VERSION ""

NS_ :

BS_:

BU_: Sensors VCU

BO_ 1628 XCP_msg: 8 Sensors

BO_ 0 LOJNK: 8 Vector__XXX

BO_ 2047 HIJNK: 8 Vector__XXX

BO_ 515 CMD03: 8 VCU
 SG_ DataChan2_s3 : 31|16@0+ (1,0) [0|0] ""  Sensors
 SG_ PageSel_s3 : 3|4@0+ (1,0) [0|0] ""  Sensors
 SG_ SensYLoc_s3 m2 : 15|16@0- (0.001,0) [0|0] "m"  Sensors
 SG_ SensXLoc_s3 m1 : 15|16@0- (0.001,0) [0|0] "m"  Sensors
 SG_ SensRotation_s3 m0 : 15|12@0- (0.1,0) [0|0] "deg"  Sensors
 SG_ SensOrientation_s3 m0 : 19|1@0+ (1,0) [0|0] ""  Sensors
 SG_ CRC8_s3 : 47|8@0+ (1,0) [0|0] ""  Sensors
 SG_ Cntr_s3 M : 7|4@0+ (1,0) [0|0] ""  Sensors
 SG_ BumperLoc_s3 m0 : 18|1@0+ (1,0) [0|0] ""  Sensors

BO_ 514 CMD02: 8 VCU
 SG_ SensYLoc_s2 m2 : 15|16@0- (0.001,0) [0|0] "m"  Sensors
 SG_ SensXLoc_s2 m1 : 15|16@0- (0.001,0) [0|0] "m"  Sensors
 SG_ SensRotation_s2 m0 : 15|12@0- (0.1,0) [0|0] "deg"  Sensors
 SG_ SensOrientation_s2 m0 : 19|1@0+ (1,0) [0|0] ""  Sensors
 SG_ PageSel_s2 : 3|4@0+ (1,0) [0|0] ""  Sensors
 SG_ DataChan2_s2 : 31|16@0+ (1,0) [0|0] ""  Sensors
 SG_ CRC8_s2 : 47|8@0+ (1,0) [0|0] ""  Sensors
 SG_ Cntr_s2 M : 7|4@0+ (1,0) [0|0] ""  Sensors
 SG_ BumperLoc_s2 m0 : 18|1@0+ (1,0) [0|0] ""  Sensors

BO_ 777 TRG9: 8 Sensors
 SG_ VeloYFilt m2 : 49|10@0- (0.1,-20) [-71.2|31.1] "m/s"  VCU
 SG_ ObjectType m2 : 51|2@0+ (1,0) [0|3] ""  VCU
 SG_ VeloXFilt m2 : 11|10@0- (0.1,-20) [-71.2|31.1] "m/s"  VCU
 SG_ RangeFilt m2 : 7|12@0+ (0.05,0) [0|204.75] "m"  VCU
 SG_ BearFilt m2 : 17|10@0- (0.2,0) [0|0] "deg"  VCU
 SG_ sID M : 43|4@0+ (1,0) [0|4] ""  VCU
 SG_ tID m2 : 35|4@0+ (1,0) [0|0] ""  VCU
 SG_ TargetType m2 : 55|4@0+ (1,0) [0|0] ""  VCU
 SG_ Quality m2 : 39|4@0+ (1,0) [0|0] ""  VCU
 SG_ mCntr m2 : 47|4@0+ (1,0) [0|0] ""  VCU

BO_ 776 TRG8: 8 Sensors
 SG_ VeloYFilt m2 : 49|10@0- (0.1,-20) [-71.2|31.1] "m/s"  VCU
 SG_ ObjectType m2 : 51|2@0+ (1,0) [0|3] ""  VCU
 SG_ VeloXFilt m2 : 11|10@0- (0.1,-20) [-71.2|31.1] "m/s"  VCU
 SG_ RangeFilt m2 : 7|12@0+ (0.05,0) [0|204.75] "m"  VCU
 SG_ BearFilt m2 : 17|10@0- (0.2,0) [0|0] "deg"  VCU
 SG_ sID M : 43|4@0+ (1,0) [1|4] ""  VCU
 SG_ tID m2 : 35|4@0+ (1,0) [0|0] ""  VCU
 SG_ TargetType m2 : 55|4@0+ (1,0) [0|0] ""  VCU
 SG_ Quality m2 : 39|4@0+ (1,0) [0|0] ""  VCU
 SG_ mCntr m2 : 47|4@0+ (1,0) [0|0] ""  VCU

BO_ 775 TRG7: 8 Sensors
 SG_ VeloYFilt m2 : 49|10@0- (0.1,-20) [-71.2|31.1] "m/s"  VCU
 SG_ ObjectType m2 : 51|2@0+ (1,0) [0|3] ""  VCU
 SG_ VeloXFilt m2 : 11|10@0- (0.1,-20) [-71.2|31.1] "m/s"  VCU
 SG_ RangeFilt m2 : 7|12@0+ (0.05,0) [0|204.75] "m"  VCU
 SG_ BearFilt m2 : 17|10@0- (0.2,0) [0|0] "deg"  VCU
 SG_ sID M : 43|4@0+ (1,0) [1|4] ""  VCU
 SG_ tID m2 : 35|4@0+ (1,0) [0|0] ""  VCU
 SG_ TargetType m2 : 55|4@0+ (1,0) [0|0] ""  VCU
 SG_ Quality m2 : 39|4@0+ (1,0) [0|0] ""  VCU
 SG_ mCntr m2 : 47|4@0+ (1,0) [0|0] ""  VCU

BO_ 774 TRG6: 8 Sensors
 SG_ VeloYFilt m2 : 49|10@0- (0.1,-20) [-71.2|31.1] "m/s"  VCU
 SG_ ObjectType m2 : 51|2@0+ (1,0) [0|3] ""  VCU
 SG_ VeloXFilt m2 : 11|10@0- (0.1,-20) [-71.2|31.1] "m/s"  VCU
 SG_ RangeFilt m2 : 7|12@0+ (0.05,0) [0|204.75] "m"  VCU
 SG_ BearFilt m2 : 17|10@0- (0.2,0) [0|0] "deg"  VCU
 SG_ sID M : 43|4@0+ (1,0) [1|4] ""  VCU
 SG_ tID m2 : 35|4@0+ (1,0) [0|0] ""  VCU
 SG_ TargetType m2 : 55|4@0+ (1,0) [0|0] ""  VCU
 SG_ Quality m2 : 39|4@0+ (1,0) [0|0] ""  VCU
 SG_ mCntr m2 : 47|4@0+ (1,0) [0|0] ""  VCU

BO_ 773 TRG5: 8 Sensors
 SG_ VeloYFilt m2 : 49|10@0- (0.1,-20) [-71.2|31.1] "m/s"  VCU
 SG_ ObjectType m2 : 51|2@0+ (1,0) [0|3] ""  VCU
 SG_ VeloXFilt m2 : 11|10@0- (0.1,-20) [-71.2|31.1] "m/s"  VCU
 SG_ RangeFilt m2 : 7|12@0+ (0.05,0) [0|204.75] "m"  VCU
 SG_ BearFilt m2 : 17|10@0- (0.2,0) [0|0] "deg"  VCU
 SG_ sID M : 43|4@0+ (1,0) [1|4] ""  VCU
 SG_ tID m2 : 35|4@0+ (1,0) [0|0] ""  VCU
 SG_ TargetType m2 : 55|4@0+ (1,0) [0|0] ""  VCU
 SG_ Quality m2 : 39|4@0+ (1,0) [0|0] ""  VCU
 SG_ mCntr m2 : 47|4@0+ (1,0) [0|0] ""  VCU

BO_ 772 TRG4: 8 Sensors
 SG_ VeloYFilt m2 : 49|10@0- (0.1,-20) [-71.2|31.1] "m/s"  VCU
 SG_ ObjectType m2 : 51|2@0+ (1,0) [0|3] ""  VCU
 SG_ VeloXFilt m2 : 11|10@0- (0.1,-20) [-71.2|31.1] "m/s"  VCU
 SG_ RangeFilt m2 : 7|12@0+ (0.05,0) [0|204.75] "m"  VCU
 SG_ BearFilt m2 : 17|10@0- (0.2,0) [0|0] "deg"  VCU
 SG_ sID M : 43|4@0+ (1,0) [1|4] ""  VCU
 SG_ tID m2 : 35|4@0+ (1,0) [0|0] ""  VCU
 SG_ TargetType m2 : 55|4@0+ (1,0) [0|0] ""  VCU
 SG_ Quality m2 : 39|4@0+ (1,0) [0|0] ""  VCU
 SG_ mCntr m2 : 47|4@0+ (1,0) [0|0] ""  VCU

BO_ 771 TRG3: 8 Sensors
 SG_ VeloYFilt m2 : 49|10@0- (0.1,-20) [-71.2|31.1] "m/s"  VCU
 SG_ ObjectType m2 : 51|2@0+ (1,0) [0|3] ""  VCU
 SG_ VeloXFilt m2 : 11|10@0- (0.1,-20) [-71.2|31.1] "m/s"  VCU
 SG_ RangeFilt m2 : 7|12@0+ (0.05,0) [0|204.75] "m"  VCU
 SG_ BearFilt m2 : 17|10@0- (0.2,0) [0|0] "deg"  VCU
 SG_ sID M : 43|4@0+ (1,0) [1|4] ""  VCU
 SG_ tID m2 : 35|4@0+ (1,0) [0|0] ""  VCU
 SG_ TargetType m2 : 55|4@0+ (1,0) [0|0] ""  VCU
 SG_ Quality m2 : 39|4@0+ (1,0) [0|0] ""  VCU
 SG_ mCntr m2 : 47|4@0+ (1,0) [0|0] ""  VCU

BO_ 770 TRG2: 8 Sensors
 SG_ VeloYFilt m2 : 49|10@0- (0.1,-20) [-71.2|31.1] "m/s"  VCU
 SG_ ObjectType m2 : 51|2@0+ (1,0) [0|3] ""  VCU
 SG_ VeloXFilt m2 : 11|10@0- (0.1,-20) [-71.2|31.1] "m/s"  VCU
 SG_ RangeFilt m2 : 7|12@0+ (0.05,0) [0|204.75] "m"  VCU
 SG_ BearFilt m2 : 17|10@0- (0.2,0) [-102.4|102.2] "deg"  VCU
 SG_ sID M : 43|4@0+ (1,0) [1|4] ""  VCU
 SG_ tID m2 : 35|4@0+ (1,0) [0|0] ""  VCU
 SG_ TargetType m2 : 55|4@0+ (1,0) [0|0] ""  VCU
 SG_ Quality m2 : 39|4@0+ (1,0) [0|0] ""  VCU
 SG_ mCntr m2 : 47|4@0+ (1,0) [0|0] ""  VCU

BO_ 769 TRG1: 8 Sensors
 SG_ VeloYFilt m2 : 49|10@0- (0.1,-20) [-71.2|31.1] "m/s"  VCU
 SG_ ObjectType m2 : 51|2@0+ (1,0) [0|3] ""  VCU
 SG_ VeloXFilt m2 : 11|10@0- (0.1,-20) [-71.2|31.1] "m/s"  VCU
 SG_ RangeFilt m2 : 7|12@0+ (0.05,0) [0|204.75] "m"  VCU
 SG_ BearFilt m2 : 17|10@0- (0.2,0) [-102.4|102.2] "deg"  VCU
 SG_ sID M : 43|4@0+ (1,0) [1|4] ""  VCU
 SG_ tID m2 : 35|4@0+ (1,0) [0|0] ""  VCU
 SG_ TargetType m2 : 55|4@0+ (1,0) [0|0] ""  VCU
 SG_ Quality m2 : 39|4@0+ (1,0) [0|0] ""  VCU
 SG_ mCntr m2 : 47|4@0+ (1,0) [0|0] ""  VCU

BO_ 768 TRG0: 8 Sensors
 SG_ VeloYFilt m2 : 49|10@0- (0.1,-20) [-71.2|31.1] "m/s"  VCU
 SG_ ObjectType m2 : 51|2@0+ (1,0) [0|3] ""  VCU
 SG_ VeloXFilt m2 : 11|10@0- (0.1,-20) [-71.2|31.1] "m/s"  VCU
 SG_ RangeFilt m2 : 7|12@0+ (0.05,0) [0|204.75] "m"  VCU
 SG_ BearFilt m2 : 17|10@0- (0.2,0) [-102.4|102.2] "deg"  VCU
 SG_ sID M : 43|4@0+ (1,0) [1|4] ""  VCU
 SG_ tID m2 : 35|4@0+ (1,0) [0|0] ""  VCU
 SG_ TargetType m2 : 55|4@0+ (1,0) [0|0] ""  VCU
 SG_ Quality m2 : 39|4@0+ (1,0) [0|0] ""  VCU
 SG_ mCntr m2 : 47|4@0+ (1,0) [0|0] ""  VCU

BO_ 1024 STAT: 8 Sensors
 SG_ AppSubVer_stat m9 : 15|8@0+ (1,0) [0|0] ""  Sensors
 SG_ AppPlatType_stat m9 : 7|8@0+ (1,0) [0|0] ""  Sensors
 SG_ AppCust_stat m10 : 15|8@0+ (1,0) [0|0] ""  Sensors
 SG_ CRC_Stat : 55|16@0+ (1,0) [0|0] ""  Sensors
 SG_ BumperLoc_stat m4 : 10|1@0+ (1,0) [0|0] ""  Sensors
 SG_ VCO_DAC m8 : 7|16@0- (0.1,0) [0|0] "deg"  Sensors
 SG_ SensYLoc_stat m6 : 7|16@0- (0.001,0) [0|0] "m"  Sensors
 SG_ SensXLoc_stat m5 : 7|16@0- (0.001,0) [0|0] "m"  Sensors
 SG_ SensRotation_stat m7 : 7|12@0- (0.1,0) [0|0] "deg"  Sensors
 SG_ SensOrientation_stat m4 : 11|1@0+ (1,0) [0|0] ""  Sensors
 SG_ PlatformType_stat m4 : 15|4@0+ (1,0) [0|15] ""  Sensors
 SG_ HW_Version m1 : 7|16@0- (1,0) [0|0] ""  Sensors
 SG_ BootSWVer_Minor m3 : 15|8@0- (1,0) [0|0] ""  Sensors
 SG_ BootSWVer_Major m3 : 7|8@0- (1,0) [0|0] ""  Sensors
 SG_ AppSWVer_Minor m2 : 15|8@0- (1,0) [0|0] ""  Sensors
 SG_ AppSWVer_Major m2 : 7|8@0- (1,0) [0|0] ""  Sensors
 SG_ PCU_Temp m0 : 15|8@0- (1,0) [0|0] "deg"  Sensors
 SG_ VCO_Temp m0 : 7|8@0- (1,0) [0|0] "deg"  Sensors
 SG_ SenMode_Stat : 39|4@0+ (1,0) [0|0] ""  Sensors
 SG_ Sen_Blockage : 35|2@0+ (1,0) [0|0] ""  Sensors
 SG_ MsgCntr_Stat M : 47|4@0+ (1,0) [0|0] ""  Sensors
 SG_ mSenNumb_Stat : 43|4@0+ (1,0) [0|0] ""  Sensors
 SG_ DiagCode_Stat : 23|16@0+ (1,0) [0|0] ""  Sensors

BO_ 256 SYNC: 8 VCU
 SG_ ProtocolRev_sync m0 : 39|8@0+ (1,0) [0|0] ""  Sensors
 SG_ PlatformType_sync m0 : 23|8@0+ (1,0) [0|255] ""  Sensors
 SG_ Msg_Cntr_sync M : 31|4@0+ (1,0) [0|0] ""  Sensors
 SG_ Vehicle_Yaw : 47|12@0- (0.05,0) [0|0] "deg/s"  Sensors
 SG_ Vehicle_Velo : 51|12@0- (0.035,0) [0|0] "m/s"  Sensors
 SG_ mode_s4 : 11|4@0+ (1,0) [0|0] ""  Sensors
 SG_ mode_s3 : 15|4@0+ (1,0) [0|0] ""  Sensors
 SG_ mode_s2 : 3|4@0+ (1,0) [0|0] ""  Sensors
 SG_ mode_s1 : 7|4@0+ (1,0) [0|0] ""  Sensors

BO_ 897 MEAS2: 8 Sensors
 SG_ SenNum_MD2 M : 43|4@0+ (1,0) [1|4] ""  VCU
 SG_ MD9 m1 : 15|8@0- (0.5,0) [0|0] "dB"  VCU
 SG_ MD8 m1 : 7|8@0- (1,0) [0|0] ""  VCU
 SG_ MD2_Msg_Cntr m1 : 47|4@0+ (1,0) [0|0] ""  VCU
 SG_ MD14 m1 : 55|8@0- (1,0) [0|0] "%"  VCU
 SG_ MD13 m1 : 63|8@0- (1,0) [0|0] ""  VCU
 SG_ MD12 m1 : 39|8@0- (1,0) [0|0] ""  VCU
 SG_ MD11 m1 : 31|8@0- (0.1,0) [0|0] "V"  VCU
 SG_ MD10 m1 : 23|8@0- (0.5,0) [0|0] "dB"  VCU

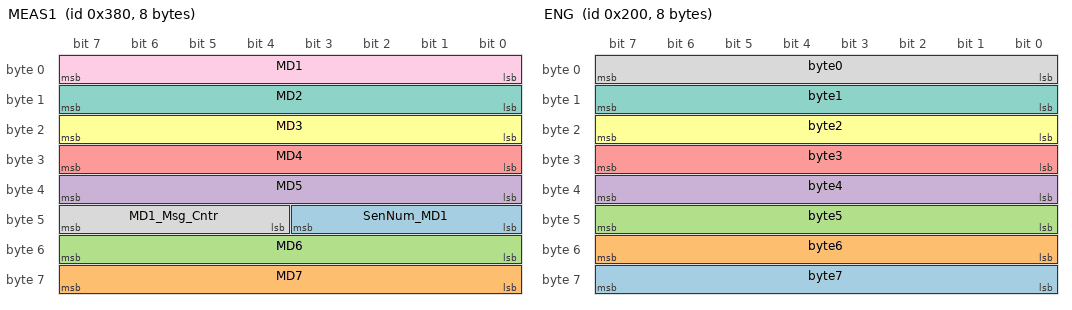
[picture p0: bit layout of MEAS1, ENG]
BO_ 896 MEAS1: 8 Sensors
 SG_ SenNum_MD1 : 43|4@0+ (1,0) [0|15] ""  VCU
 SG_ MD7 : 63|8@0- (1,0) [0|0] ""  VCU
 SG_ MD6 : 55|8@0- (1,0) [0|0] ""  VCU
 SG_ MD5 : 39|8@0- (0.5,0) [0|0] "m/s"  VCU
 SG_ MD4 : 31|8@0- (0.5,0) [0|0] "dB"  VCU
 SG_ MD3 : 23|8@0- (0.5,0) [0|0] "dB"  VCU
 SG_ MD2 : 15|8@0- (0.5,0) [0|0] "dB"  VCU
 SG_ MD1_Msg_Cntr : 47|4@0+ (1,0) [0|0] ""  VCU
 SG_ MD1 : 7|8@0- (0.6,0) [0|0] "dB"  VCU

BO_ 1023 ERR: 8 Sensors
 SG_ ErrorState_9 : 19|2@0+ (1,0) [0|0] ""  VCU
 SG_ ErrorState_8 : 17|2@0+ (1,0) [0|0] ""  VCU
 SG_ ErrorState_7 : 15|2@0+ (1,0) [0|0] ""  VCU
 SG_ ErrorState_6 : 13|2@0+ (1,0) [0|0] ""  VCU
 SG_ ErrorState_5 : 11|2@0+ (1,0) [0|0] ""  VCU
 SG_ ErrorState_4 : 9|2@0+ (1,0) [0|0] ""  VCU
 SG_ ErrorState_3 : 7|2@0+ (1,0) [0|0] ""  VCU
 SG_ ErrorState_27 : 63|2@0+ (1,0) [0|0] ""  VCU
 SG_ ErrorState_26 : 61|2@0+ (1,0) [0|0] ""  VCU
 SG_ ErrorState_25 : 59|2@0+ (1,0) [0|0] ""  VCU
 SG_ ErrorState_24 : 57|2@0+ (1,0) [0|0] ""  VCU
 SG_ ErrorState_23 : 55|2@0+ (1,0) [0|0] ""  VCU
 SG_ ErrorState_22 : 53|2@0+ (1,0) [0|0] ""  VCU
 SG_ ErrorState_21 : 51|2@0+ (1,0) [0|0] ""  VCU
 SG_ ErrorState_20 : 49|2@0+ (1,0) [0|0] ""  VCU
 SG_ ErrorState_2 : 5|2@0+ (1,0) [0|0] ""  VCU
 SG_ ErrorState_19 : 39|2@0+ (1,0) [0|0] ""  VCU
 SG_ ErrorState_18 : 37|2@0+ (1,0) [0|0] ""  VCU
 SG_ ErrorState_17 : 35|2@0+ (1,0) [0|0] ""  VCU
 SG_ ErrorState_16 : 33|2@0+ (1,0) [0|0] ""  VCU
 SG_ ErrorState_15 : 31|2@0+ (1,0) [0|0] ""  VCU
 SG_ ErrorState_14 : 29|2@0+ (1,0) [0|0] ""  VCU
 SG_ ErrorState_13 : 27|2@0+ (1,0) [0|0] ""  VCU
 SG_ ErrorState_12 : 25|2@0+ (1,0) [0|0] ""  VCU
 SG_ ErrorState_11 : 23|2@0+ (1,0) [0|0] ""  VCU
 SG_ ErrorState_10 : 21|2@0+ (1,0) [0|0] ""  VCU
 SG_ ErrorState_1 : 3|2@0+ (1,0) [0|0] ""  VCU
 SG_ ErrorState_0 : 1|2@0+ (1,0) [0|0] ""  VCU
 SG_ Err_SenNum : 43|4@0+ (1,0) [0|0] ""  VCU
 SG_ Err_MsgCntr : 47|4@0+ (1,0) [0|0] ""  VCU

BO_ 512 ENG: 8 VCU
 SG_ byte7 : 63|8@0+ (1,0) [0|255] ""  Sensors
 SG_ byte6 : 55|8@0+ (1,0) [0|255] ""  Sensors
 SG_ byte5 : 47|8@0+ (1,0) [0|255] ""  Sensors
 SG_ byte4 : 39|8@0+ (1,0) [0|255] ""  Sensors
 SG_ byte3 : 31|8@0+ (1,0) [0|255] ""  Sensors
 SG_ byte2 : 23|8@0+ (1,0) [0|255] ""  Sensors
 SG_ byte1 : 15|8@0+ (1,0) [0|255] ""  Sensors
 SG_ byte0 : 7|8@0+ (1,0) [0|0] ""  Sensors

BO_ 516 CMD04: 8 VCU
 SG_ SensYLoc_s4 m2 : 15|16@0- (0.001,0) [0|0] "m"  Sensors
 SG_ SensXLoc_s4 m1 : 15|16@0- (0.001,0) [0|0] "m"  Sensors
 SG_ SensRotation_s4 m0 : 15|12@0- (0.1,0) [0|0] "deg"  Sensors
 SG_ SensOrientation_s4 m0 : 19|1@0+ (1,0) [0|0] ""  Sensors
 SG_ BumperLoc_s4 m0 : 18|1@0+ (1,0) [0|0] ""  Sensors
 SG_ PageSel_s4 : 3|4@0+ (1,0) [0|0] ""  Sensors
 SG_ DataChan2_s4 : 31|16@0+ (1,0) [0|0] ""  Sensors
 SG_ CRC8_s4 : 47|8@0+ (1,0) [0|0] ""  Sensors
 SG_ Cntr_s4 M : 7|4@0+ (1,0) [0|0] ""  Sensors

BO_ 513 CMD01: 8 VCU
 SG_ BumperLoc_s1 m0 : 18|1@0+ (1,0) [0|0] ""  Sensors
 SG_ SensYLoc_s1 m2 : 15|16@0- (0.001,0) [0|0] "m"  Sensors
 SG_ SensXLoc_s1 m1 : 15|16@0- (0.001,0) [0|0] "m"  Sensors
 SG_ SensRotation_s1 m0 : 15|12@0- (0.1,0) [0|0] "deg"  Sensors
 SG_ SensOrientation_s1 m0 : 19|1@0+ (1,0) [0|0] ""  Sensors
 SG_ PageSel_s1 : 3|4@0+ (1,0) [0|0] ""  Sensors
 SG_ DataChan2_s1 : 31|16@0+ (1,0) [0|0] ""  Sensors
 SG_ CRC8_s1 : 47|8@0+ (1,0) [0|0] ""  Sensors
 SG_ Cntr_s1 M : 7|4@0+ (1,0) [0|0] ""  Sensors

BA_DEF_ BO_  "FBlock" STRING ;
BA_DEF_ BO_  "FunctionClass" ENUM  "Property","Method";
BA_DEF_  "E2EP01ProfileName" STRING ;
BA_DEF_  "E2EP01ProfileBehavior" ENUM  "PRE_R4_2","R4_2";
BA_DEF_  "BusBaudateData" INT 0 10000;
BA_DEF_  "E2EP01DataIdMode" ENUM  "all16Bit","alternating8Bit","lower8Bit","lower12Bit";
BA_DEF_ BO_  "GenMsgSendType" ENUM  "Cyclic","NotUsed","NotUsed","NotUsed","NotUsed","NotUsed","NotUsed","IfActive","NoMsgSendType";
BA_DEF_  "BusBaudateOther" INT 0 10000;
BA_DEF_ BO_  "GenMsgCycleTime" INT 0 0;
BA_DEF_ SG_  "GenSigStartValue" INT 0 0;
BA_DEF_ SG_  "GenSigSendType" ENUM  "Cyclic","OnWrite","OnWriteWithRepetition","OnChange","OnChangeWithRepetition","IfActive","IfActiveWithRepetition","NoSigSendType";
BA_DEF_ BO_  "GenMsgCycleTimeFast" INT 0 0;
BA_DEF_ BO_  "GenMsgDelayTime" INT 0 0;
BA_DEF_  "DBName" STRING ;
BA_DEF_  "BusBaudrate" INT 0 10000;
BA_DEF_ BU_  "NodeLayerModules" STRING ;
BA_DEF_ BU_  "ILUsed" ENUM  "No","Yes";
BA_DEF_ BU_  "DiagStationAddress" HEX 0 255;
BA_DEF_ BO_  "CANFD_BRS" ENUM  "0","1";
BA_DEF_ BO_  "VFrameFormat" ENUM  "StandardCAN","ExtendedCAN","reserved","reserved","reserved","reserved","reserved","reserved","reserved","reserved","reserved","reserved","reserved","reserved","StandardCAN_FD","ExtendedCAN_FD";
BA_DEF_ BO_  "GenMsgILSupport" ENUM  "No","Yes";
BA_DEF_  "BusType" STRING ;
BA_DEF_DEF_  "FBlock" "GeneralBlock";
BA_DEF_DEF_  "FunctionClass" "Property";
BA_DEF_DEF_  "E2EP01ProfileName" "PROFILE_01";
BA_DEF_DEF_  "E2EP01ProfileBehavior" "R4_2";
BA_DEF_DEF_  "BusBaudateData" 2;
BA_DEF_DEF_  "E2EP01DataIdMode" "lower8Bit";
BA_DEF_DEF_  "GenMsgSendType" "Cyclic";
BA_DEF_DEF_  "BusBaudateOther" 500;
BA_DEF_DEF_  "GenMsgCycleTime" 0;
BA_DEF_DEF_  "GenSigStartValue" 0;
BA_DEF_DEF_  "GenSigSendType" "Cyclic";
BA_DEF_DEF_  "GenMsgCycleTimeFast" 0;
BA_DEF_DEF_  "GenMsgDelayTime" 0;
BA_DEF_DEF_  "DBName" "";
BA_DEF_DEF_  "BusBaudrate" 500;
BA_DEF_DEF_  "NodeLayerModules" "CANoeILNLVector.dll";
BA_DEF_DEF_  "ILUsed" "Yes";
BA_DEF_DEF_  "DiagStationAddress" 0;
BA_DEF_DEF_  "CANFD_BRS" "1";
BA_DEF_DEF_  "VFrameFormat" "StandardCAN";
BA_DEF_DEF_  "GenMsgILSupport" "Yes";
BA_DEF_DEF_  "BusType" "MOST";
BA_ "BusType" "CAN FD";
BA_ "BusBaudrate" 2000;
BA_ "DBName" "CAN_LRR_CENTER";
BA_ "DiagStationAddress" BU_ VCU 174;
BA_ "GenMsgSendType" BO_ 1628 8;
BA_ "GenMsgSendType" BO_ 0 8;
BA_ "GenMsgSendType" BO_ 2047 8;
BA_ "GenMsgSendType" BO_ 515 8;
BA_ "GenMsgCycleTime" BO_ 514 50;
BA_ "GenMsgCycleTimeFast" BO_ 514 50;
BA_ "GenMsgDelayTime" BO_ 514 2;
BA_ "GenMsgSendType" BO_ 777 8;
BA_ "GenMsgSendType" BO_ 776 8;
BA_ "GenMsgSendType" BO_ 775 8;
BA_ "GenMsgSendType" BO_ 774 8;
BA_ "GenMsgSendType" BO_ 773 8;
BA_ "GenMsgSendType" BO_ 772 8;
BA_ "GenMsgSendType" BO_ 771 8;
BA_ "GenMsgSendType" BO_ 770 8;
BA_ "GenMsgSendType" BO_ 769 8;
BA_ "GenMsgSendType" BO_ 768 8;
BA_ "GenMsgSendType" BO_ 1024 8;
BA_ "GenMsgCycleTime" BO_ 256 50;
BA_ "GenMsgCycleTimeFast" BO_ 256 50;
BA_ "GenMsgSendType" BO_ 897 8;
BA_ "GenMsgSendType" BO_ 896 8;
BA_ "GenMsgSendType" BO_ 1023 8;
BA_ "GenMsgSendType" BO_ 512 8;
BA_ "GenMsgSendType" BO_ 516 8;
BA_ "GenMsgILSupport" BO_ 513 0;
BA_ "GenMsgSendType" BO_ 513 8;
BA_ "GenSigStartValue" SG_ 776 sID 1;
BA_ "GenSigStartValue" SG_ 775 sID 1;
BA_ "GenSigStartValue" SG_ 774 sID 1;
BA_ "GenSigStartValue" SG_ 773 sID 1;
BA_ "GenSigStartValue" SG_ 772 sID 1;
BA_ "GenSigStartValue" SG_ 771 sID 1;
BA_ "GenSigStartValue" SG_ 770 sID 1;
BA_ "GenSigStartValue" SG_ 769 sID 1;
BA_ "GenSigStartValue" SG_ 768 sID 1;
BA_ "GenSigStartValue" SG_ 897 SenNum_MD2 1;
VAL_ 515 SensOrientation_s3 1 "Upside Down - 1" 0 "Normal - 0" ;
VAL_ 515 BumperLoc_s3 1 "Rear - 1" 0 "Front - 0" ;
VAL_ 514 SensOrientation_s2 1 "Upside Down - 1" 0 "Normal - 0" ;
VAL_ 514 BumperLoc_s2 1 "Rear - 1" 0 "Front - 0" ;
VAL_ 777 ObjectType 3 "Tracked - 3" 2 "Moving - 2" 1 "Stationary - 1" 0 "Unknown - 0" ;
VAL_ 776 ObjectType 3 "Tracked - 3" 2 "Moving - 2" 1 "Stationary - 1" 0 "Unknown - 0" ;
VAL_ 775 ObjectType 3 "Tracked - 3" 2 "Moving - 2" 1 "Stationary - 1" 0 "Unknown - 0" ;
VAL_ 774 ObjectType 3 "Tracked - 3" 2 "Moving - 2" 1 "Stationary - 1" 0 "Unknown - 0" ;
VAL_ 773 ObjectType 3 "Tracked - 3" 2 "Moving - 2" 1 "Stationary - 1" 0 "Unknown - 0" ;
VAL_ 772 ObjectType 3 "Tracked - 3" 2 "Moving - 2" 1 "Stationary - 1" 0 "Unknown - 0" ;
VAL_ 771 ObjectType 3 "Tracked - 3" 2 "Moving - 2" 1 "Stationary - 1" 0 "Unknown - 0" ;
VAL_ 770 ObjectType 3 "Tracked - 3" 2 "Moving - 2" 1 "Stationary - 1" 0 "Unknown - 0" ;
VAL_ 769 ObjectType 3 "Tracked - 3" 2 "Moving - 2" 1 "Stationary - 1" 0 "Unknown - 0" ;
VAL_ 768 ObjectType 3 "Tracked - 3" 2 "Moving - 2" 1 "Stationary - 1" 0 "Unknown - 0" ;
VAL_ 1024 BumperLoc_stat 1 "Rear - 1" 0 "Front - 0" ;
VAL_ 1024 SensOrientation_stat 1 "Upside Down - 1" 0 "Normal - 0" ;
VAL_ 1024 SenMode_Stat 15 "Transition - 0xf" 14 "Calibration - 0xe" 5 "Blind Spot - 5" 4 "Short Pulse - 4" 3 "Reserved - 3" 2 "Long Pulse - 2" 1 "Idle - 1" 0 "Reset - 0 " ;
VAL_ 1024 Sen_Blockage 3 "Preclean - 3" 2 "Full Block - 2" 1 "Preblock - 1" 0 "Clean - 0" ;
VAL_ 516 SensOrientation_s4 1 "Upside Down - 1" 0 "Normal - 0" ;
VAL_ 516 BumperLoc_s4 1 "Rear - 1" 0 "Front - 0" ;
VAL_ 513 BumperLoc_s1 1 "Rear - 1" 0 "Front - 0" ;
VAL_ 513 SensOrientation_s1 1 "Upside Down - 1" 0 "Normal - 0" ;
